VERSION ""

NS_ :

BS_:

BU_: DCU_HIL Computer PDU_HIL VCU_HIL

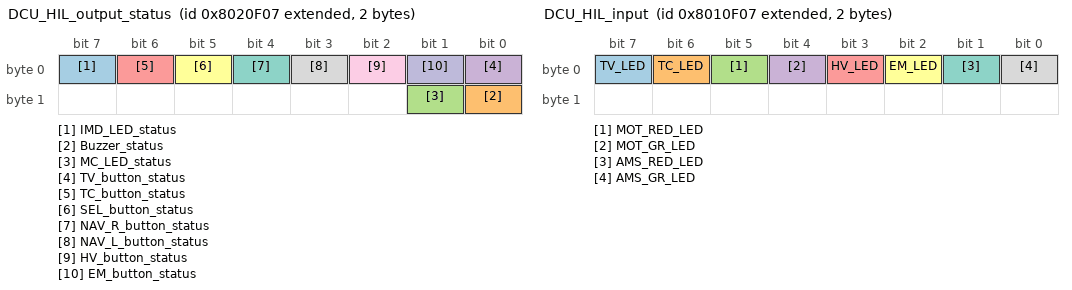
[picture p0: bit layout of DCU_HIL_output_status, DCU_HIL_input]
BO_ 2281836295 DCU_HIL_output_status: 2 DCU_HIL
 SG_ IMD_LED_status : 7|1@1+ (1,0) [0|1] "" Vector__XXX
 SG_ Buzzer_status : 8|1@1+ (1,0) [0|1] "" Vector__XXX
 SG_ MC_LED_status : 9|1@1+ (1,0) [0|1] "" Vector__XXX
 SG_ TV_button_status : 0|1@1+ (1,0) [0|1] ""  Computer
 SG_ TC_button_status : 6|1@1+ (1,0) [0|1] ""  Computer
 SG_ SEL_button_status : 5|1@1+ (1,0) [0|1] ""  Computer
 SG_ NAV_R_button_status : 4|1@1+ (1,0) [0|1] ""  Computer
 SG_ NAV_L_button_status : 3|1@1+ (1,0) [0|1] ""  Computer
 SG_ HV_button_status : 2|1@1+ (1,0) [0|1] ""  Computer
 SG_ EM_button_status : 1|1@1+ (1,0) [0|1] ""  Computer

BO_ 2281770759 DCU_HIL_input: 2 DCU_HIL
 SG_ TV_LED : 7|1@1+ (1,0) [0|1] "" Vector__XXX
 SG_ TC_LED : 6|1@1+ (1,0) [0|1] "" Vector__XXX
 SG_ MOT_RED_LED : 5|1@1+ (1,0) [0|1] "" Vector__XXX
 SG_ MOT_GR_LED : 4|1@1+ (1,0) [0|1] "" Vector__XXX
 SG_ HV_LED : 3|1@1+ (1,0) [0|1] "" Vector__XXX
 SG_ EM_LED : 2|1@1+ (1,0) [0|1] "" Vector__XXX
 SG_ AMS_RED_LED : 1|1@1+ (1,0) [0|1] "" Vector__XXX
 SG_ AMS_GR_LED : 0|1@1+ (1,0) [0|1] "" Vector__XXX

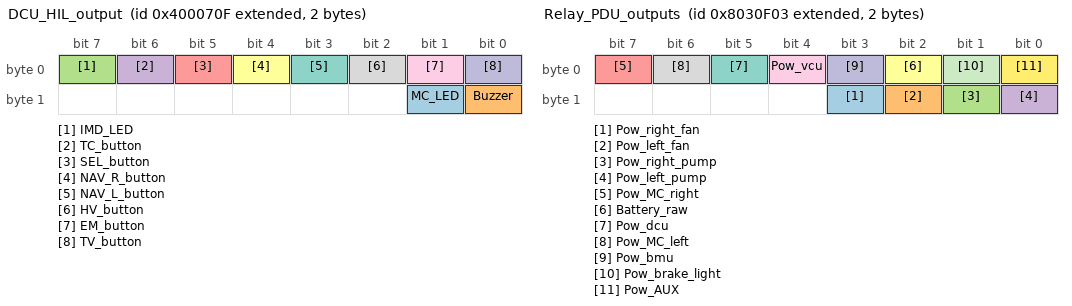
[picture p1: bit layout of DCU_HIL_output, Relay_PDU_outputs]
BO_ 2214594319 DCU_HIL_output: 2 Computer
 SG_ MC_LED : 9|1@1+ (1,0) [0|1] "" Vector__XXX
 SG_ Buzzer : 8|1@1+ (1,0) [0|1] "" Vector__XXX
 SG_ IMD_LED : 7|1@1+ (1,0) [0|1] "" Vector__XXX
 SG_ TC_button : 6|1@1+ (1,0) [0|1] ""  DCU_HIL
 SG_ SEL_button : 5|1@1+ (1,0) [0|1] ""  DCU_HIL
 SG_ NAV_R_button : 4|1@1+ (1,0) [0|1] ""  DCU_HIL
 SG_ NAV_L_button : 3|1@1+ (1,0) [0|1] ""  DCU_HIL
 SG_ HV_button : 2|1@1+ (1,0) [0|1] ""  DCU_HIL
 SG_ EM_button : 1|1@1+ (1,0) [0|1] ""  DCU_HIL
 SG_ TV_button : 0|1@1+ (1,0) [0|1] ""  DCU_HIL

BO_ 2281901827 Relay_PDU_outputs: 2 PDU_HIL
 SG_ Pow_right_fan : 11|1@1+ (1,0) [0|1] ""  Computer
 SG_ Pow_left_fan : 10|1@1+ (1,0) [0|1] ""  Computer
 SG_ Pow_right_pump : 9|1@1+ (1,0) [0|1] ""  Computer
 SG_ Pow_left_pump : 8|1@1+ (1,0) [0|1] ""  Computer
 SG_ Pow_MC_right : 7|1@1+ (1,0) [0|1] ""  Computer
 SG_ Battery_raw : 2|1@1+ (1,0) [0|1] ""  Computer
 SG_ Pow_dcu : 5|1@1+ (1,0) [0|1] ""  Computer
 SG_ Pow_MC_left : 6|1@1+ (1,0) [0|1] ""  Computer
 SG_ Pow_vcu : 4|1@1+ (1,0) [0|1] ""  Computer
 SG_ Pow_bmu : 3|1@1+ (1,0) [0|1] ""  Computer
 SG_ Pow_brake_light : 1|1@1+ (1,0) [0|1] ""  Computer
 SG_ Pow_AUX : 0|1@1+ (1,0) [0|1] ""  Computer

BO_ 2281836291 PDU_message_status: 1 PDU_HIL
 SG_ Batt_thermistor_status : 0|1@1+ (1,0) [0|1] ""  Computer

BO_ 2214658831 Batt_thermistor: 3 Computer
 SG_ Batt_thermistor : 0|18@1+ (1,0) [60|200060] "Ohm"  PDU_HIL

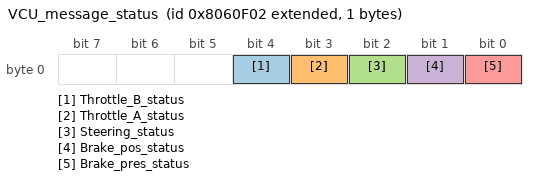
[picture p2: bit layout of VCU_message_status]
BO_ 2282098434 VCU_message_status: 1 VCU_HIL
 SG_ Throttle_B_status : 4|1@1+ (1,0) [0|1] ""  Computer
 SG_ Throttle_A_status : 3|1@1+ (1,0) [0|1] ""  Computer
 SG_ Steering_status : 2|1@1+ (1,0) [0|1] ""  Computer
 SG_ Brake_pos_status : 1|1@1+ (1,0) [0|1] ""  Computer
 SG_ Brake_pres_status : 0|1@1+ (1,0) [0|1] ""  Computer

BO_ 2214920719 Steering_raw: 2 Computer
 SG_ Steering_raw : 0|12@1+ (1,0) [0|3300] "mV"  VCU_HIL

BO_ 2214855183 Brake_position: 2 Computer
 SG_ Brake_position : 0|12@1+ (1,0) [0|3300] "mV"  VCU_HIL

BO_ 2214789647 Brake_pres_raw: 2 Computer
 SG_ Brake_pres_raw : 0|12@1+ (1,0) [0|3300] "mV"  VCU_HIL

BO_ 2214724111 Throttle_position_B: 2 Computer
 SG_ Throttle_position_B : 0|12@1+ (1,0) [0|3300] "mV"  VCU_HIL

BO_ 2214658575 Throttle_position_A: 2 Computer
 SG_ Throttle_position_A : 0|12@1+ (1,0) [0|3300] "mV"  VCU_HIL

CM_ SG_ 2214658575 Throttle_position_A "
";
BA_DEF_  "BusType" STRING ;
BA_DEF_DEF_  "BusType" "CAN";
